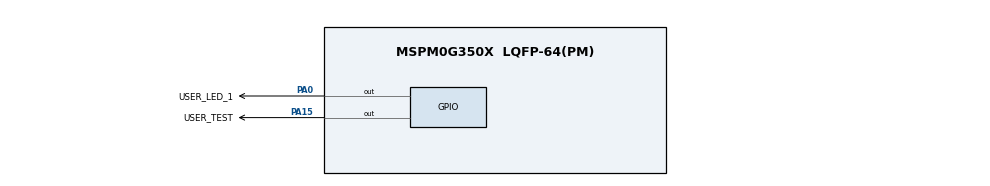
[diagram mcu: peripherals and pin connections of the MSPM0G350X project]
/**
 * @cliArgs --device "MSPM0G350X" --part "Default" --package "LQFP-64(PM)" --product "mspm0_sdk@2.10.00.04"
 * @versions {"tool":"1.26.2+4477"}
 */

/**
 * Import the modules used in this configuration.
 */
const GPIO   = scripting.addModule("/ti/driverlib/GPIO", {}, false);
const GPIO1  = GPIO.addInstance();
const SYSCTL = scripting.addModule("/ti/driverlib/SYSCTL");
const TIMER  = scripting.addModule("/ti/driverlib/TIMER", {}, false);
const TIMER1 = TIMER.addInstance();

/**
 * Write custom configuration values to the imported modules.
 */
GPIO1.$name                          = "GPIO_LEDS";
GPIO1.associatedPins.create(2);
GPIO1.associatedPins[0].$name        = "USER_TEST";
GPIO1.associatedPins[0].assignedPort = "PORTA";
GPIO1.associatedPins[0].pin.$assign  = "PA15";
GPIO1.associatedPins[1].$name        = "USER_LED_1";
GPIO1.associatedPins[1].initialValue = "SET";
GPIO1.associatedPins[1].assignedPort = "PORTA";
GPIO1.associatedPins[1].assignedPin  = "0";
GPIO1.associatedPins[1].pin.$assign  = "PA0";

const Board = scripting.addModule("/ti/driverlib/Board", {}, false);

SYSCTL.forceDefaultClkConfig = true;

TIMER1.$name              = "TIMER_0";
TIMER1.timerPeriod        = "50 ms";
TIMER1.interrupts         = ["ZERO"];
TIMER1.peripheral.$assign = "TIMG12";

/**
 * Pinmux solution for unlocked pins/peripherals. This ensures that minor changes to the automatic solver in a future
 * version of the tool will not impact the pinmux you originally saw.  These lines can be completely deleted in order to
 * re-solve from scratch.
 */
Board.peripheral.$suggestSolution          = "DEBUGSS";
Board.peripheral.swclkPin.$suggestSolution = "PA20";
Board.peripheral.swdioPin.$suggestSolution = "PA19";
SYSCTL.peripheral.$suggestSolution         = "SYSCTL";
